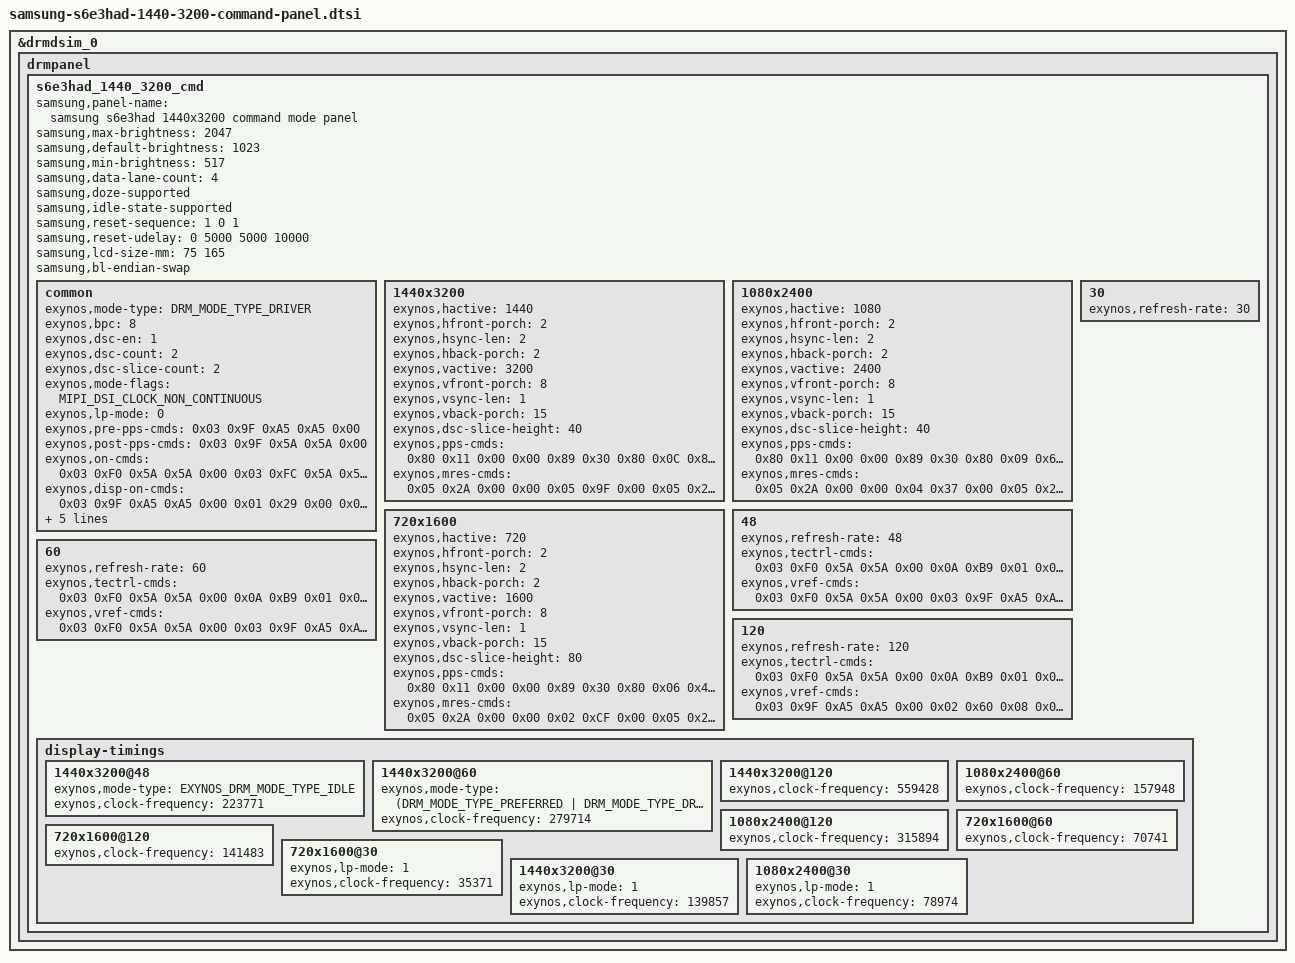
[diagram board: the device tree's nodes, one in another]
#include <dt-bindings/display/exynos-display.h>
#include <dt-bindings/display/exynos-mipi-display.h>

&drmdsim_0 {
	drmpanel {
		s6e3had_1440_3200_cmd: s6e3had_1440_3200_cmd {
			samsung,panel-name = "samsung s6e3had 1440x3200 command mode panel";
			samsung,max-brightness = <2047>;
			samsung,default-brightness = <1023>;
			samsung,min-brightness = <517>;
			samsung,data-lane-count = <4>;
			samsung,doze-supported;
			samsung,idle-state-supported;

			samsung,reset-sequence = <1 0 1>;
			samsung,reset-udelay = <0 5000 5000 10000>;

			samsung,lcd-size-mm = <75 165>; /* width x height */
			samsung,bl-endian-swap;

			/* common info & cmds */
			common {
				exynos,mode-type = <DRM_MODE_TYPE_DRIVER>;

				exynos,bpc = <8>;
				exynos,dsc-en = <1>;
				exynos,dsc-count = <2>;
				exynos,dsc-slice-count = <2>;

				exynos,mode-flags = <MIPI_DSI_CLOCK_NON_CONTINUOUS>;
				exynos,lp-mode = <0>;

				exynos,pre-pps-cmds = <
					0x03 0x9F 0xA5 0xA5 0x00
					>;
				exynos,post-pps-cmds = <
					0x03 0x9F 0x5A 0x5A 0x00
					>;
				exynos,on-cmds = <
					0x03 0xF0 0x5A 0x5A 0x00
					0x03 0xFC 0x5A 0x5A 0x00
					/* sleep out: 200ms delay */
					0x01 0x11 0xC8
					/* Typical high duration */
					0x0A 0xB9 0x00 0x0C 0x8C 0x00 0x09 0x00 0x00 0x00 0x00 0x00
					/*  enable brightness control */
					0x02 0x53 0x20 0x00

					/* WRDISBV(51h) = 1st[7:0], 2nd[15:8] */
					0x03 0x51 0xFF 0x7F 0x00

					/* TE on */
					0x01 0x35 0x00

					/* ESD flag: [2]=VLIN3, [6]=VLIN1 error check */
					0x03 0xED 0x04 0x44 0x00

					/* SEQ_FFC */
					/* 0x0D 0xC5 0x09 0x10 0x68 0x45 0x3B 0x9A 0x3B 0x9A 0x3B 0x9A 0x3B 0x9A 0x00 */
					>;
				exynos,disp-on-cmds = <
					0x03 0x9F 0xA5 0xA5 0x00
					0x01 0x29 0x00
					0x03 0x9F 0x5A 0x5A 0x00
					>;

				exynos,off-cmds = <
					0x01 0x28 0x00
					0x01 0x10 0x00
					>;

				exynos,panel-close-cmds = <
					0x03 0x9F 0xA5 0xA5 0x00
					/* 0x22 : PIXEL OFF, 0x28 : DISP OFF */
					0x01 0x28 0x00
					0x03 0x9F 0x5A 0x5A 0x00
					>;

				exynos,panel-open-cmds = <
					0x03 0x9F 0xA5 0xA5 0x00
					/* 0x13 : NORMAL ON, 0x29 : DISP ON */
					0x01 0x29 0x00
					0x03 0x9F 0x5A 0x5A 0x00
					>;
			};
			/* resolution dependent info & cmds */
			1440x3200 {
				exynos,hactive = <1440>;
				exynos,hfront-porch = <2>;
				exynos,hsync-len = <2>;
				exynos,hback-porch = <2>;
				exynos,vactive = <3200>;
				exynos,vfront-porch = <8>;
				exynos,vsync-len = <1>;
				exynos,vback-porch = <15>;

				exynos,dsc-slice-height = <40>;

				exynos,pps-cmds = <
					0x80
					0x11 0x00 0x00 0x89 0x30 0x80 0x0C 0x80
					0x05 0xA0 0x00 0x28 0x02 0xD0 0x02 0xD0
					0x02 0x00 0x02 0x68 0x00 0x20 0x04 0x6C
					0x00 0x0A 0x00 0x0C 0x02 0x77 0x01 0xE9
					0x18 0x00 0x10 0xF0 0x03 0x0C 0x20 0x00
					0x06 0x0B 0x0B 0x33 0x0E 0x1C 0x2A 0x38
					0x46 0x54 0x62 0x69 0x70 0x77 0x79 0x7B
					0x7D 0x7E 0x01 0x02 0x01 0x00 0x09 0x40
					0x09 0xBE 0x19 0xFC 0x19 0xFA 0x19 0xF8
					0x1A 0x38 0x1A 0x78 0x1A 0xB6 0x2A 0xF6
					0x2B 0x34 0x2B 0x74 0x3B 0x74 0x6B 0xF4
					0x00 0x00 0x00 0x00 0x00 0x00 0x00 0x00
					0x00 0x00 0x00 0x00 0x00 0x00 0x00 0x00
					0x00 0x00 0x00 0x00 0x00 0x00 0x00 0x00
					0x00 0x00 0x00 0x00 0x00 0x00 0x00 0x00
					0x00 0x00 0x00 0x00 0x00 0x00 0x00 0x00
					0x00
					>;

				exynos,mres-cmds = <
					0x05 0x2A 0x00 0x00 0x05 0x9F 0x00
					0x05 0x2B 0x00 0x00 0x0C 0x7F 0x00
					0x03 0xF0 0x5A 0x5A 0x00
					0x02 0xBA 0x01 0x00
					0x03 0xF0 0xA5 0xA5 0x00
					>;
			};
			1080x2400 {
				exynos,hactive = <1080>;
				exynos,hfront-porch = <2>;
				exynos,hsync-len = <2>;
				exynos,hback-porch = <2>;
				exynos,vactive = <2400>;
				exynos,vfront-porch = <8>;
				exynos,vsync-len = <1>;
				exynos,vback-porch = <15>;

				exynos,dsc-slice-height = <40>;

				exynos,pps-cmds = <
					0x80
					0x11 0x00 0x00 0x89 0x30 0x80 0x09 0x60
					0x04 0x38 0x00 0x28 0x02 0x1C 0x02 0x1C
					0x02 0x00 0x02 0x0E 0x00 0x20 0x03 0xDD
					0x00 0x07 0x00 0x0C 0x02 0x77 0x02 0x8B
					0x18 0x00 0x10 0xF0 0x03 0x0C 0x20 0x00
					0x06 0x0B 0x0B 0x33 0x0E 0x1C 0x2A 0x38
					0x46 0x54 0x62 0x69 0x70 0x77 0x79 0x7B
					0x7D 0x7E 0x01 0x02 0x01 0x00 0x09 0x40
					0x09 0xBE 0x19 0xFC 0x19 0xFA 0x19 0xF8
					0x1A 0x38 0x1A 0x78 0x1A 0xB6 0x2A 0xF6
					0x2B 0x34 0x2B 0x74 0x3B 0x74 0x6B 0xF4
					0x00 0x00 0x00 0x00 0x00 0x00 0x00 0x00
					0x00 0x00 0x00 0x00 0x00 0x00 0x00 0x00
					0x00 0x00 0x00 0x00 0x00 0x00 0x00 0x00
					0x00 0x00 0x00 0x00 0x00 0x00 0x00 0x00
					0x00 0x00 0x00 0x00 0x00 0x00 0x00 0x00
					0x00
					>;
				exynos,mres-cmds = <
					0x05 0x2A 0x00 0x00 0x04 0x37 0x00
					0x05 0x2B 0x00 0x00 0x09 0x5F 0x00
					0x03 0xF0 0x5A 0x5A 0x00
					0x02 0xBA 0x02 0x00
					0x03 0xF0 0xA5 0xA5 0x00
					>;
			};
			720x1600 {
				exynos,hactive = <720>;
				exynos,hfront-porch = <2>;
				exynos,hsync-len = <2>;
				exynos,hback-porch = <2>;
				exynos,vactive = <1600>;
				exynos,vfront-porch = <8>;
				exynos,vsync-len = <1>;
				exynos,vback-porch = <15>;

				exynos,dsc-slice-height = <80>;

				exynos,pps-cmds = <
					0x80
					0x11 0x00 0x00 0x89 0x30 0x80 0x06 0x40
					0x02 0xD0 0x00 0x50 0x01 0x68 0x01 0x68
					0x02 0x00 0x01 0xB4 0x00 0x20 0x06 0x2F
					0x00 0x05 0x00 0x0C 0x01 0x38 0x01 0xE9
					0x18 0x00 0x10 0xF0 0x03 0x0C 0x20 0x00
					0x06 0x0B 0x0B 0x33 0x0E 0x1C 0x2A 0x38
					0x46 0x54 0x62 0x69 0x70 0x77 0x79 0x7B
					0x7D 0x7E 0x01 0x02 0x01 0x00 0x09 0x40
					0x09 0xBE 0x19 0xFC 0x19 0xFA 0x19 0xF8
					0x1A 0x38 0x1A 0x78 0x1A 0xB6 0x2A 0xF6
					0x2B 0x34 0x2B 0x74 0x3B 0x74 0x6B 0xF4
					0x00 0x00 0x00 0x00 0x00 0x00 0x00 0x00
					0x00 0x00 0x00 0x00 0x00 0x00 0x00 0x00
					0x00 0x00 0x00 0x00 0x00 0x00 0x00 0x00
					0x00 0x00 0x00 0x00 0x00 0x00 0x00 0x00
					0x00 0x00 0x00 0x00 0x00 0x00 0x00 0x00
					0x00
					>;
				exynos,mres-cmds = <
					0x05 0x2A 0x00 0x00 0x02 0xCF 0x00
					0x05 0x2B 0x00 0x00 0x06 0x3F 0x00
					0x03 0xF0 0x5A 0x5A 0x00
					0x02 0xBA 0x00 0x00
					0x03 0xF0 0xA5 0xA5 0x00
					>;
			};

			/* framerate dependent info & cmds */
			30 {
				exynos,refresh-rate = <30>;
			};
			48 {
				exynos,refresh-rate = <48>;
				exynos,tectrl-cmds = <
					0x03 0xF0 0x5A 0x5A 0x00
					/* TE start timing is advanced by about 1msec */
					0x0A 0xB9 0x01 0x0B 0xC4 0x00 0x09 0x00 0x00 0x00 0x00 0x00
					0x03 0xF0 0xA5 0xA5 0x00
					>;
				exynos,vref-cmds = <
					0x03 0xF0 0x5A 0x5A 0x00
					0x03 0x9F 0xA5 0xA5 0x00
					0x02 0x60 0x00 0x00
					0x03 0x9F 0x5A 0x5A 0x00
					0x04 0xB0 0x00 0x0D 0xF2 0x00
					0x03 0xF2 0x03 0x3C 0x00
					0x02 0xF7 0x0F 0x00
					0x03 0xF0 0xA5 0xA5 0x00
					>;
			};
			60 {
				exynos,refresh-rate = <60>;
				exynos,tectrl-cmds = <
					0x03 0xF0 0x5A 0x5A 0x00
					/* TE start timing is advanced by about 1msec */
					0x0A 0xB9 0x01 0x0B 0xC4 0x00 0x09 0x00 0x00 0x00 0x00 0x00
					0x03 0xF0 0xA5 0xA5 0x00
					>;
				exynos,vref-cmds = <
					0x03 0xF0 0x5A 0x5A 0x00
					0x03 0x9F 0xA5 0xA5 0x00
					0x02 0x60 0x00 0x00
					0x03 0x9F 0x5A 0x5A 0x00
					0x04 0xB0 0x00 0x0D 0xF2 0x00
					0x03 0xF2 0x00 0x10 0x00
					0x02 0xF7 0x0F 0x00
					0x03 0xF0 0xA5 0xA5 0x00
					>;
			};
			120 {
				exynos,refresh-rate = <120>;
				exynos,tectrl-cmds = <
					0x03 0xF0 0x5A 0x5A 0x00
					/* TE start timing is advanced by about 1msec */
					0x0A 0xB9 0x01 0x0A 0xFC 0x00 0x09 0x00 0x00 0x00 0x00 0x00
					0x03 0xF0 0xA5 0xA5 0x00
					>;
				exynos,vref-cmds = <
					0x03 0x9F 0xA5 0xA5 0x00
					0x02 0x60 0x08 0x00
					0x03 0x9F 0x5A 0x5A 0x00
					0x04 0xB0 0x00 0x0D 0xF2 0x00
					0x03 0xF2 0x00 0x10 0x00
					0x02 0xF7 0x0F 0x00
					0x03 0xF0 0xA5 0xA5 0x00
					>;
			};

			display-timings {
				/*
				* The exynos properties can be declared repeatedly in any node.
				* The properties of child nodes have a high priority
				* than properties of parent node.
				*/
				1440x3200@48 {
					exynos,mode-type = <EXYNOS_DRM_MODE_TYPE_IDLE>;
					exynos,clock-frequency = <223771>;
				};
				1440x3200@60 {
					exynos,mode-type = <(DRM_MODE_TYPE_PREFERRED |
							DRM_MODE_TYPE_DRIVER)>;
					exynos,clock-frequency = <279714>;
				};
				1440x3200@120 {
					exynos,clock-frequency = <559428>;
				};
				1080x2400@60 {
					exynos,clock-frequency = <157948>;
				};
				1080x2400@120 {
					exynos,clock-frequency = <315894>;
				};
				720x1600@60 {
					exynos,clock-frequency = <70741>;
				};
				720x1600@120 {
					exynos,clock-frequency = <141483>;
				};
				720x1600@30 {
					exynos,lp-mode = <1>;
					exynos,clock-frequency = <35371>;
				};
				1440x3200@30 {
					exynos,lp-mode = <1>;
					exynos,clock-frequency = <139857>;
				};
				1080x2400@30 {
					exynos,lp-mode = <1>;
					exynos,clock-frequency = <78974>;
				};
			};
		};
	};
};
